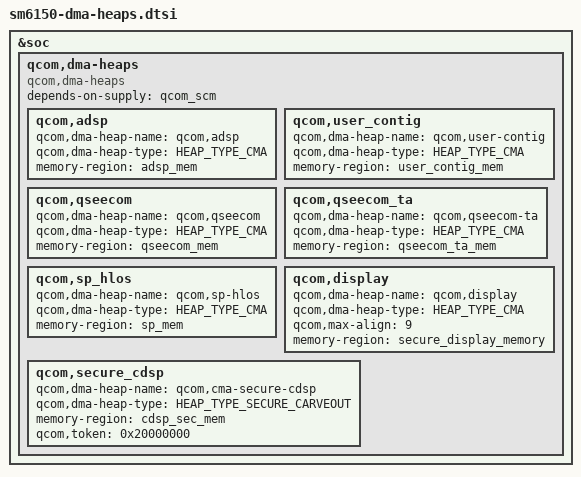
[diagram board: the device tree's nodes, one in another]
// SPDX-License-Identifier: BSD-3-Clause
/*
 * Copyright (c) Qualcomm Technologies, Inc. and/or its subsidiaries.
 */

#include <dt-bindings/arm/msm/qcom_dma_heap_dt_constants.h>

&soc {
	qcom,dma-heaps {
		compatible = "qcom,dma-heaps";
		depends-on-supply = <&qcom_scm>;

		qcom,adsp { /* ADSP HEAP */
			qcom,dma-heap-name = "qcom,adsp";
			qcom,dma-heap-type = <HEAP_TYPE_CMA>;
			memory-region = <&adsp_mem>;
		};

		qcom,user_contig { /* USER CONTIG HEAP */
			qcom,dma-heap-name = "qcom,user-contig";
			qcom,dma-heap-type = <HEAP_TYPE_CMA>;
			memory-region = <&user_contig_mem>;
		};

		qcom,qseecom { /* QSEECOM HEAP */
			qcom,dma-heap-name = "qcom,qseecom";
			qcom,dma-heap-type = <HEAP_TYPE_CMA>;
			memory-region = <&qseecom_mem>;
		};

		qcom,qseecom_ta { /* QSEECOM TA HEAP */
			qcom,dma-heap-name = "qcom,qseecom-ta";
			qcom,dma-heap-type = <HEAP_TYPE_CMA>;
			memory-region = <&qseecom_ta_mem>;
		};

		qcom,sp_hlos { /* SPSS HEAP */
			qcom,dma-heap-name = "qcom,sp-hlos";
			qcom,dma-heap-type = <HEAP_TYPE_CMA>;
			memory-region = <&sp_mem>;
		};

		qcom,display { /* SECURE DISPLAY HEAP */
			qcom,dma-heap-name = "qcom,display";
			qcom,dma-heap-type = <HEAP_TYPE_CMA>;
			qcom,max-align = <9>;
			memory-region = <&secure_display_memory>;
		};

		qcom,secure_cdsp { /* SECURE CARVEOUT HEAP */
			qcom,dma-heap-name = "qcom,cma-secure-cdsp";
			qcom,dma-heap-type = <HEAP_TYPE_SECURE_CARVEOUT>;
			memory-region = <&cdsp_sec_mem>;
			qcom,token = <0x20000000>;
		};

	};
};
